# RTS5918 register map
Vendor: Realtek Semiconductor Corp.; Series: RTS5918 Series; File version: 1.00
CPU: ARMV8MML r0p0, little endian, MPU, FPU, VTOR, 3 interrupt priority bits, 8 SAU regions
Registers are 32-bit, read-write, reset 0x0 unless marked. A register's access mark holds for its fields unless they carry their own. Offsets are from the block's base; [hi:lo] are bit positions; {n}, {i} and the like mark numbered series.

## UART — UART Controller
Base 0x40251600
Same registers: UART1 0x40251700, UART2 0x40251800
0x00 RBR ro — RECEIVE BUFFER REGISTER
  [7:0] DATA — Receive Buffer
0x00 THR (alternate view of RBR) — TRANSMIT HOLDING REGISTER
  [7:0] DATA — Transmit Holding
0x00 DLL (alternate view of RBR) — DIVISOR LATCH LOW REGISTER
  [7:0] DIVL — Divisor Latch Low Byte
0x04 DLH — DIVISOR LATCH HIGH REGISTER
  [7:0] DIVH — Divisor Latch High Byte
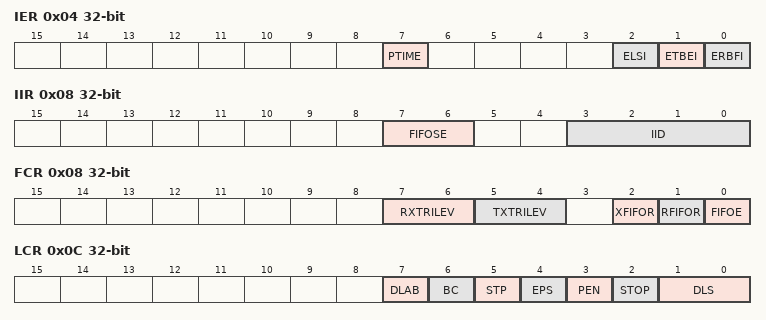
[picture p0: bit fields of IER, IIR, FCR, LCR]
0x04 IER (alternate view of DLH) — INTRRRUPT ENABLE REGISTER
  [7] PTIME — Programmable THRE Interrupt Mode Enable
    0=DISABLE (Disable programmable THRE interrupt mode); 1=ENABLE (Enable programmable THRE interrupt mode)
  [2] ELSI — Enable Receiver Line Status Interrupt
    0=DISABLE (Disable receiver line status interrupt); 1=ENABLE (Enable receiver line status interrupt)
  [1] ETBEI — Enable Transmit Holding Register Empty Interrupt
    0=DISABLE (Disable transmit holding register empty interrupt); 1=ENABLE (Enable transmit holding register empty interrupt)
  [0] ERBFI — Enable Received Data Available Interrupt
    0=DISABLE (Disable received data available interrupt); 1=ENABLE (Enable received data available interrupt)
0x08 IIR ro — INTERRUPT IDENTIFICATION
  [7:6] FIFOSE — FIFOs Enabled
    0=DISABLE (FIFOs is disabled); 3=ENABLE (FIFOs is enabled); other=NOT_USED (Reserved values. Do not use.)
  [3:0] IID — Interrupt ID
    0=MODEM (Modem status); 1=HAVE_NO_INT (No interrupt pending); 2=THR_EMPTY; 4=RX_AVL (Received data available); 6=LINE_AVL (Receiver line status); 7=BUSY_DET (Busy detect); 12=CHAR_TO (Character Timeout); other=NOT_USED (Reserved values. Do not use.)
0x08 FCR (alternate view of IIR) — FIFO CONTROL REGISTER
  [7:6] RXTRILEV — Rx Trigger Level
  [5:4] TXTRILEV — TX Empty Trigger Level
  [2] XFIFOR — Tx FIFO Reset
  [1] RFIFOR — Rx FIFO Reset
  [0] FIFOE — FIFO Enabled
0x0C LCR — LINE CONTROL REGISTER
  [7] DLAB — Divisor Latch Access Bit
    0=DISABLE (Disable divisor latch access); 1=ENABLE (Enable divisor latch access)
  [6] BC — Break Control Bit
    0=DISABLE (Disable break control); 1=ENABLE (Enable break control)
  [5] STP — Stick Parity
    0=DISABLE (Disable stick parity); 1=ENABLE (Enable stick parity)
  [4] EPS — Even Parity Select
    0=ODD (Odd parity); 1=EVEN (Even parity)
  [3] PEN — Parity Enable
    0=DISABLE (Disable parity); 1=ENABLE (Enable parity)
  [2] STOP — Number of Stop Bits
    0=1_BIT (1 stop bit); 1=1_5_BIT (1.5 stop bits when DLS (LCR[1:0]) is 0, else 2 stop bit)
  [1:0] DLS — Data Length Select
    {v}={v+5}_BIT (Data Length is {v+5}-bit) (v=0..3)
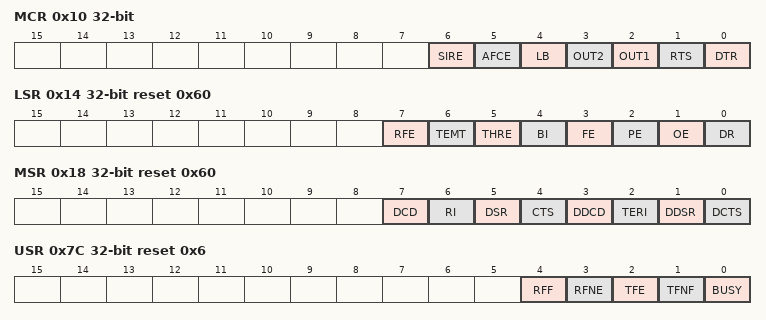
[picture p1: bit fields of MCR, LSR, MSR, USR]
0x10 MCR — MODEM CONTROL REGISTER
  [6] SIRE — SIR Mode Enable
    0=DISABLE (IrDA SIR disable); 1=ENABLE (IrDA SIR enable)
  [5] AFCE — Auto Flow Control Enable
    0=DISABLE (Auto Flow Control disable); 1=ENABLE (Auto Flow Control enable)
  [4] LB — LoopBack
    0=DISABLE (LoopBack disable); 1=ENABLE (LoopBack enable)
  [3] OUT2
    0=DISABLE (OUT2_n deasserted); 1=ENABLE (OUT2_n asserted)
  [2] OUT1
    0=DISABLE (OUT1_n deasserted); 1=ENABLE (OUT1_n asserted)
  [1] RTS — Request to Send
    0=DISABLE (RTS_n deasserted); 1=ENABLE (RTS_n asserted)
  [0] DTR — Data Terminal Ready
    0=DISABLE (DTR_n deasserted); 1=ENABLE (DTR_n asserted)
0x14 LSR ro reset 0x60 — LINE STATUS REGISTER
  [7] RFE — Receiver FIFO Error
    0=NO_ERR (No receiver FIFO error); 1=ERR (Receiver FIFO error occrred)
  [6] TEMT — Transmitter Empty Bit
    0=NOT_EMPTY (No transmitter empty); 1=EMPTY (Transmitter empty)
  [5] THRE — Transmit Holding Register Empty bit
    0=NOT_EMPTY (Transmit Holding Register is not empty); 1=EMPTY (Transmit Holding Register is empty)
  [4] BI — Break Interrupt bit
    0=NO_ERR (No break interrupt); 1=ERR (Break interrupt occrred)
  [3] FE — Framing Error bit
    0=NO_ERR (No framing error); 1=ERR (framing error occrred)
  [2] PE — Parity Error bit
    0=NO_ERR (No parity error); 1=ERR (Parity error)
  [1] OE — Overrun Error bit
    0=NO_ERR (No oerrun error); 1=ERR (Overrun error)
  [0] DR — Data Ready Bit
    0=NOT_READY (No data ready); 1=READY (Data ready)
0x18 MSR ro reset 0x60 — MODEM STATUS REGISTER
  [7] DCD — Data Carrier Detect
    0=DEASSERT (DCD_n input is de-asserted); 1=ASSERT (DCD_n input is asserted)
  [6] RI — Ring Indicator
    0=DEASSERT (RI_n input is de-asserted); 1=ASSERT (RI_n input is asserted)
  [5] DSR — Data Set Ready
    0=DEASSERT (DSR_n input is de-asserted); 1=ASSERT (DSR_n input is asserted)
  [4] CTS — Clear to Send
    0=DEASSERT (CTS_n input is de-asserted); 1=ASSERT (CTS_n input is asserted)
  [3] DDCD — Delta Data Carrier Detect
    0=NONE (No change on dcd_n since last read of MSR); 1=CHANGED (Change on dcd_n since last read of MSR)
  [2] TERI — Trailing Edge of Ring Indicator
    0=NONE (No change on ri_n since last read of MSR); 1=CHANGED (Change on ri_n since last read of MSR)
  [1] DDSR — Delta Data Set Ready
    0=NONE (No change on dsr_n since last read of MSR); 1=CHANGED (Change on dsr_n since last read of MSR)
  [0] DCTS — Data Clear to Send
    0=NONE (No change on cts_n since last read of MSR); 1=CHANGED (change on cts_n since last read of MSR)
0x7C USR ro reset 0x6 — UART Status Register
  [4] RFF — Receive FIFO Full
    0=NOT_FULL (Receive FIFO not full); 1=FULL (Receive FIFO Full)
  [3] RFNE — Receive FIFO Not Empty
    0=EMPTY (Receive FIFO is empty); 1=NOT_EMPTY (Receive FIFO is not empty)
  [2] TFE — Transmit FIFO Empty
    0=NOT_EMPTY (Transmit FIFO is not empty); 1=EMPTY (Transmit FIFO is empty)
  [1] TFNF — Transmit FIFO Not Full
    0=FULL (Transmit FIFO is full); 1=NOT_FULL (Transmit FIFO is not full)
  [0] BUSY — UART Busy
    0=IDLE (UART idle or inactive); 1=BUSY (UART is busy)
0x80 TFL ro — UART TRANSMIT FIFO LEVEL
0x84 RFL ro — UART RECEIVE FIFO LEVEL
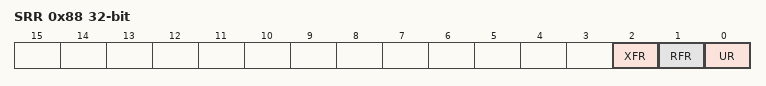
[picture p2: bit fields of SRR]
0x88 SRR wo — UART SOFTWARE RESET REGISTER
  [2] XFR — XMIT FIFO Reset
  [1] RFR — RCVR FIFO Reset
  [0] UR — UART Reset
